# STM32F765BGT6 register map
File version: 1.0
Registers are 32-bit, access not given, reset 0x0 unless marked. A register's access mark holds for its fields unless they carry their own. Offsets are from the block's base; [hi:lo] are bit positions; {n}, {i} and the like mark numbered series.

## JPEG
Base 0x50051000
0x00 CONFR0
  [0] START
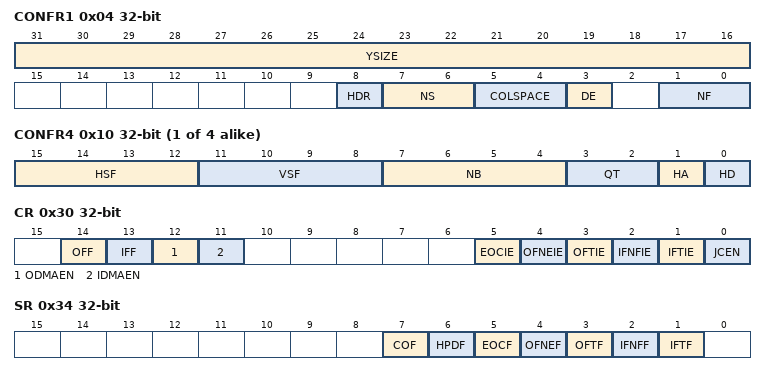
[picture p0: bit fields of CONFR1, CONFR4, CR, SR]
0x04 CONFR1
  [31:16] YSIZE, [8] HDR, [7:6] NS, [5:4] COLSPACE, [3] DE, [1:0] NF
0x08 CONFR2
  [25:0] NMCU
0x0C CONFR3
  [31:16] XSIZE
{0x0+4i} CONFR{i} (i=4..7)
  [15:12] HSF, [11:8] VSF, [7:4] NB, [3:2] QT, [1] HA, [0] HD
0x30 CR
  [14] OFF, [13] IFF, [12] ODMAEN, [11] IDMAEN, [5] EOCIE, [4] OFNEIE, [3] OFTIE, [2] IFNFIE, [1] IFTIE, [0] JCEN
0x34 SR
  [7] COF, [6] HPDF, [5] EOCF, [4] OFNEF, [3] OFTF, [2] IFNFF, [1] IFTF
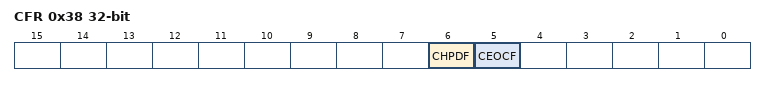
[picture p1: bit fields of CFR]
0x38 CFR
  [6] CHPDF, [5] CEOCF
0x40 DIR
  [31:0] DATAIN
0x44 DOR
  [31:0] DATAOUT
0x50 QMEM.0
0x54 QMEM.1
0x58 QMEM.2
0x5C QMEM.3
0x60 QMEM.4
0x64 QMEM.5
0x68 QMEM.6
0x6C QMEM.7
0x70 QMEM.8
0x74 QMEM.9
0x78 QMEM.10
0x7C QMEM.11
0x80 QMEM.12
0x84 QMEM.13
0x88 QMEM.14
0x8C QMEM.15
0x90 QMEM.16
0x94 QMEM.17
0x98 QMEM.18
0x9C QMEM.19
0xA0 QMEM.20
0xA4 QMEM.21
0xA8 QMEM.22
0xAC QMEM.23
0xB0 QMEM.24
0xB4 QMEM.25
0xB8 QMEM.26
0xBC QMEM.27
0xC0 QMEM.28
0xC4 QMEM.29
0xC8 QMEM.30
0xCC QMEM.31
0xD0 QMEM.32
0xD4 QMEM.33
0xD8 QMEM.34
0xDC QMEM.35
0xE0 QMEM.36
0xE4 QMEM.37
0xE8 QMEM.38
0xEC QMEM.39
0xF0 QMEM.40
0xF4 QMEM.41
0xF8 QMEM.42
0xFC QMEM.43
0x100 QMEM.44
0x104 QMEM.45
0x108 QMEM.46
0x10C QMEM.47
0x110 QMEM.48
0x114 QMEM.49
0x118 QMEM.50
0x11C QMEM.51
0x120 QMEM.52
0x124 QMEM.53
0x128 QMEM.54
0x12C QMEM.55
0x130 QMEM.56
0x134 QMEM.57
0x138 QMEM.58
0x13C QMEM.59
0x140 QMEM.60
0x144 QMEM.61
0x148 QMEM.62
0x14C QMEM.63
0x150 HUFFMIN.0
0x154 HUFFMIN.1
0x158 HUFFMIN.2
0x15C HUFFMIN.3
0x160 HUFFMIN.4
0x164 HUFFMIN.5
0x168 HUFFMIN.6
0x16C HUFFMIN.7
0x170 HUFFMIN.8
0x174 HUFFMIN.9
0x178 HUFFMIN.10
0x17C HUFFMIN.11
0x180 HUFFMIN.12
0x184 HUFFMIN.13
0x188 HUFFMIN.14
0x18C HUFFMIN.15
0x190 HUFFBASE.0
0x194 HUFFBASE.1
0x198 HUFFBASE.2
0x19C HUFFBASE.3
0x1A0 HUFFBASE.4
0x1A4 HUFFBASE.5
0x1A8 HUFFBASE.6
0x1AC HUFFBASE.7
0x1B0 HUFFBASE.8
0x1B4 HUFFBASE.9
0x1B8 HUFFBASE.10
0x1BC HUFFBASE.11
0x1C0 HUFFBASE.12
0x1C4 HUFFBASE.13
0x1C8 HUFFBASE.14
0x1CC HUFFBASE.15
0x1D0 HUFFBASE.16
0x1D4 HUFFBASE.17
0x1D8 HUFFBASE.18
0x1DC HUFFBASE.19
0x1E0 HUFFBASE.20
0x1E4 HUFFBASE.21
0x1E8 HUFFBASE.22
0x1EC HUFFBASE.23
0x1F0 HUFFBASE.24
0x1F4 HUFFBASE.25
0x1F8 HUFFBASE.26
0x1FC HUFFBASE.27
0x200 HUFFBASE.28
0x204 HUFFBASE.29
0x208 HUFFBASE.30
0x20C HUFFBASE.31
0x210 HUFFSYMB.0
0x214 HUFFSYMB.1
0x218 HUFFSYMB.2
0x21C HUFFSYMB.3
0x220 HUFFSYMB.4
0x224 HUFFSYMB.5
0x228 HUFFSYMB.6
0x22C HUFFSYMB.7
0x230 HUFFSYMB.8
0x234 HUFFSYMB.9
0x238 HUFFSYMB.10
0x23C HUFFSYMB.11
0x240 HUFFSYMB.12
0x244 HUFFSYMB.13
0x248 HUFFSYMB.14
0x24C HUFFSYMB.15
0x250 HUFFSYMB.16
0x254 HUFFSYMB.17
0x258 HUFFSYMB.18
0x25C HUFFSYMB.19
0x260 HUFFSYMB.20
0x264 HUFFSYMB.21
0x268 HUFFSYMB.22
0x26C HUFFSYMB.23
0x270 HUFFSYMB.24
0x274 HUFFSYMB.25
0x278 HUFFSYMB.26
0x27C HUFFSYMB.27
0x280 HUFFSYMB.28
0x284 HUFFSYMB.29
0x288 HUFFSYMB.30
0x28C HUFFSYMB.31
0x290 HUFFSYMB.32
0x294 HUFFSYMB.33
0x298 HUFFSYMB.34
0x29C HUFFSYMB.35
0x2A0 HUFFSYMB.36
0x2A4 HUFFSYMB.37
0x2A8 HUFFSYMB.38
0x2AC HUFFSYMB.39
0x2B0 HUFFSYMB.40
0x2B4 HUFFSYMB.41
0x2B8 HUFFSYMB.42
0x2BC HUFFSYMB.43
0x2C0 HUFFSYMB.44
0x2C4 HUFFSYMB.45
0x2C8 HUFFSYMB.46
0x2CC HUFFSYMB.47
0x2D0 HUFFSYMB.48
0x2D4 HUFFSYMB.49
0x2D8 HUFFSYMB.50
0x2DC HUFFSYMB.51
0x2E0 HUFFSYMB.52
0x2E4 HUFFSYMB.53
0x2E8 HUFFSYMB.54
0x2EC HUFFSYMB.55
0x2F0 HUFFSYMB.56
0x2F4 HUFFSYMB.57
0x2F8 HUFFSYMB.58
0x2FC HUFFSYMB.59
0x300 HUFFSYMB.60
0x304 HUFFSYMB.61
0x308 HUFFSYMB.62
0x30C HUFFSYMB.63
0x310 HUFFSYMB.64
0x314 HUFFSYMB.65
0x318 HUFFSYMB.66
0x31C HUFFSYMB.67
0x320 HUFFSYMB.68
0x324 HUFFSYMB.69
0x328 HUFFSYMB.70
0x32C HUFFSYMB.71
0x330 HUFFSYMB.72
0x334 HUFFSYMB.73
0x338 HUFFSYMB.74
0x33C HUFFSYMB.75
0x340 HUFFSYMB.76
0x344 HUFFSYMB.77
0x348 HUFFSYMB.78
0x34C HUFFSYMB.79
0x350 HUFFSYMB.80
0x354 HUFFSYMB.81
0x358 HUFFSYMB.82
0x35C HUFFSYMB.83
0x360 DHTMEM.0
0x364 DHTMEM.1
0x368 DHTMEM.2
0x36C DHTMEM.3
0x370 DHTMEM.4
0x374 DHTMEM.5
0x378 DHTMEM.6
0x37C DHTMEM.7
0x380 DHTMEM.8
0x384 DHTMEM.9
0x388 DHTMEM.10
0x38C DHTMEM.11
0x390 DHTMEM.12
0x394 DHTMEM.13
0x398 DHTMEM.14
0x39C DHTMEM.15
0x3A0 DHTMEM.16
0x3A4 DHTMEM.17
0x3A8 DHTMEM.18
0x3AC DHTMEM.19
0x3B0 DHTMEM.20
0x3B4 DHTMEM.21
0x3B8 DHTMEM.22
0x3BC DHTMEM.23
0x3C0 DHTMEM.24
0x3C4 DHTMEM.25
0x3C8 DHTMEM.26
0x3CC DHTMEM.27
0x3D0 DHTMEM.28
0x3D4 DHTMEM.29
0x3D8 DHTMEM.30
0x3DC DHTMEM.31
0x3E0 DHTMEM.32
0x3E4 DHTMEM.33
0x3E8 DHTMEM.34
0x3EC DHTMEM.35
0x3F0 DHTMEM.36
0x3F4 DHTMEM.37
0x3F8 DHTMEM.38
0x3FC DHTMEM.39
0x400 DHTMEM.40
0x404 DHTMEM.41
0x408 DHTMEM.42
0x40C DHTMEM.43
0x410 DHTMEM.44
0x414 DHTMEM.45
0x418 DHTMEM.46
0x41C DHTMEM.47
0x420 DHTMEM.48
0x424 DHTMEM.49
0x428 DHTMEM.50
0x42C DHTMEM.51
0x430 DHTMEM.52
0x434 DHTMEM.53
0x438 DHTMEM.54
0x43C DHTMEM.55
0x440 DHTMEM.56
0x444 DHTMEM.57
0x448 DHTMEM.58
0x44C DHTMEM.59
0x450 DHTMEM.60
0x454 DHTMEM.61
0x458 DHTMEM.62
0x45C DHTMEM.63
0x460 DHTMEM.64
0x464 DHTMEM.65
0x468 DHTMEM.66
0x46C DHTMEM.67
0x470 DHTMEM.68
0x474 DHTMEM.69
0x478 DHTMEM.70
0x47C DHTMEM.71
0x480 DHTMEM.72
0x484 DHTMEM.73
0x488 DHTMEM.74
0x48C DHTMEM.75
0x490 DHTMEM.76
0x494 DHTMEM.77
0x498 DHTMEM.78
0x49C DHTMEM.79
0x4A0 DHTMEM.80
0x4A4 DHTMEM.81
0x4A8 DHTMEM.82
0x4AC DHTMEM.83
0x4B0 DHTMEM.84
0x4B4 DHTMEM.85
0x4B8 DHTMEM.86
0x4BC DHTMEM.87
0x4C0 DHTMEM.88
0x4C4 DHTMEM.89
0x4C8 DHTMEM.90
0x4CC DHTMEM.91
0x4D0 DHTMEM.92
0x4D4 DHTMEM.93
0x4D8 DHTMEM.94
0x4DC DHTMEM.95
0x4E0 DHTMEM.96
0x4E4 DHTMEM.97
0x4E8 DHTMEM.98
0x4EC DHTMEM.99
0x4F0 DHTMEM.100
0x4F4 DHTMEM.101
0x4F8 DHTMEM.102
0x4FC DHTMEM.103
0x500 HUFFENC.0
0x504 HUFFENC.1
0x508 HUFFENC.2
0x50C HUFFENC.3
0x510 HUFFENC.4
0x514 HUFFENC.5
0x518 HUFFENC.6
0x51C HUFFENC.7
0x520 HUFFENC.8
0x524 HUFFENC.9
0x528 HUFFENC.10
0x52C HUFFENC.11
0x530 HUFFENC.12
0x534 HUFFENC.13
0x538 HUFFENC.14
0x53C HUFFENC.15
0x540 HUFFENC.16
0x544 HUFFENC.17
0x548 HUFFENC.18
0x54C HUFFENC.19
0x550 HUFFENC.20
0x554 HUFFENC.21
0x558 HUFFENC.22
0x55C HUFFENC.23
0x560 HUFFENC.24
0x564 HUFFENC.25
0x568 HUFFENC.26
0x56C HUFFENC.27
0x570 HUFFENC.28
0x574 HUFFENC.29
0x578 HUFFENC.30
0x57C HUFFENC.31
0x580 HUFFENC.32
0x584 HUFFENC.33
0x588 HUFFENC.34
0x58C HUFFENC.35
0x590 HUFFENC.36
0x594 HUFFENC.37
0x598 HUFFENC.38
0x59C HUFFENC.39
0x5A0 HUFFENC.40
0x5A4 HUFFENC.41
0x5A8 HUFFENC.42
0x5AC HUFFENC.43
0x5B0 HUFFENC.44
0x5B4 HUFFENC.45
0x5B8 HUFFENC.46
0x5BC HUFFENC.47
0x5C0 HUFFENC.48
0x5C4 HUFFENC.49
0x5C8 HUFFENC.50
0x5CC HUFFENC.51
0x5D0 HUFFENC.52
0x5D4 HUFFENC.53
0x5D8 HUFFENC.54
0x5DC HUFFENC.55
0x5E0 HUFFENC.56
0x5E4 HUFFENC.57
0x5E8 HUFFENC.58
0x5EC HUFFENC.59
0x5F0 HUFFENC.60
0x5F4 HUFFENC.61
0x5F8 HUFFENC.62
0x5FC HUFFENC.63
0x600 HUFFENC.64
0x604 HUFFENC.65
0x608 HUFFENC.66
0x60C HUFFENC.67
0x610 HUFFENC.68
0x614 HUFFENC.69
0x618 HUFFENC.70
0x61C HUFFENC.71
0x620 HUFFENC.72
0x624 HUFFENC.73
0x628 HUFFENC.74
0x62C HUFFENC.75
0x630 HUFFENC.76
0x634 HUFFENC.77
0x638 HUFFENC.78
0x63C HUFFENC.79
0x640 HUFFENC.80
0x644 HUFFENC.81
0x648 HUFFENC.82
0x64C HUFFENC.83
0x650 HUFFENC.84
0x654 HUFFENC.85
0x658 HUFFENC.86
0x65C HUFFENC.87
0x660 HUFFENC.88
0x664 HUFFENC.89
0x668 HUFFENC.90
0x66C HUFFENC.91
0x670 HUFFENC.92
0x674 HUFFENC.93
0x678 HUFFENC.94
0x67C HUFFENC.95
0x680 HUFFENC.96
0x684 HUFFENC.97
0x688 HUFFENC.98
0x68C HUFFENC.99
0x690 HUFFENC.100
0x694 HUFFENC.101
0x698 HUFFENC.102
0x69C HUFFENC.103
0x6A0 HUFFENC.104
0x6A4 HUFFENC.105
0x6A8 HUFFENC.106
0x6AC HUFFENC.107
0x6B0 HUFFENC.108
0x6B4 HUFFENC.109
0x6B8 HUFFENC.110
0x6BC HUFFENC.111
0x6C0 HUFFENC.112
0x6C4 HUFFENC.113
0x6C8 HUFFENC.114
0x6CC HUFFENC.115
0x6D0 HUFFENC.116
0x6D4 HUFFENC.117
0x6D8 HUFFENC.118
0x6DC HUFFENC.119
0x6E0 HUFFENC.120
0x6E4 HUFFENC.121
0x6E8 HUFFENC.122
0x6EC HUFFENC.123
0x6F0 HUFFENC.124
0x6F4 HUFFENC.125
0x6F8 HUFFENC.126
0x6FC HUFFENC.127
0x700 HUFFENC.128
0x704 HUFFENC.129
0x708 HUFFENC.130
0x70C HUFFENC.131
0x710 HUFFENC.132
0x714 HUFFENC.133
0x718 HUFFENC.134
0x71C HUFFENC.135
0x720 HUFFENC.136
0x724 HUFFENC.137
0x728 HUFFENC.138
0x72C HUFFENC.139
0x730 HUFFENC.140
0x734 HUFFENC.141
0x738 HUFFENC.142
0x73C HUFFENC.143
0x740 HUFFENC.144
0x744 HUFFENC.145
0x748 HUFFENC.146
0x74C HUFFENC.147
0x750 HUFFENC.148
0x754 HUFFENC.149
0x758 HUFFENC.150
0x75C HUFFENC.151
0x760 HUFFENC.152
0x764 HUFFENC.153
0x768 HUFFENC.154
0x76C HUFFENC.155
0x770 HUFFENC.156
0x774 HUFFENC.157
0x778 HUFFENC.158
0x77C HUFFENC.159
0x780 HUFFENC.160
0x784 HUFFENC.161
0x788 HUFFENC.162
0x78C HUFFENC.163
0x790 HUFFENC.164
0x794 HUFFENC.165
0x798 HUFFENC.166
0x79C HUFFENC.167
0x7A0 HUFFENC.168
0x7A4 HUFFENC.169
0x7A8 HUFFENC.170
0x7AC HUFFENC.171
0x7B0 HUFFENC.172
0x7B4 HUFFENC.173
0x7B8 HUFFENC.174
0x7BC HUFFENC.175
0x7C0 HUFFENC.176
0x7C4 HUFFENC.177
0x7C8 HUFFENC.178
0x7CC HUFFENC.179
0x7D0 HUFFENC.180
0x7D4 HUFFENC.181
0x7D8 HUFFENC.182
0x7DC HUFFENC.183
0x7E0 HUFFENC.184
0x7E4 HUFFENC.185
0x7E8 HUFFENC.186
0x7EC HUFFENC.187
0x7F0 HUFFENC.188
0x7F4 HUFFENC.189
0x7F8 HUFFENC.190
0x7FC HUFFENC.191
